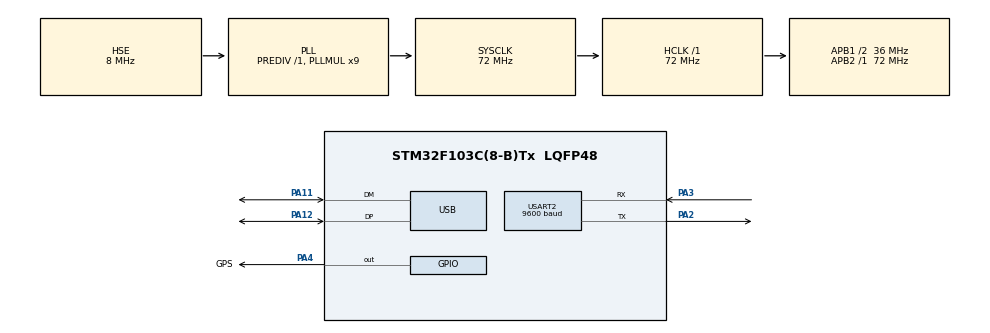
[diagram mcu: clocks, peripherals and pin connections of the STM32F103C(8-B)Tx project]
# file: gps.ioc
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Mcu.Family=STM32F1
Mcu.Name=STM32F103C(8-B)Tx
Mcu.Package=LQFP48
NVIC.PriorityGroup=NVIC_PRIORITYGROUP_4
NVIC.USART2_IRQn=true\:0\:0\:false\:false\:true\:true\:true\:true
NVIC.USB_LP_CAN1_RX0_IRQn=true\:0\:0\:false\:false\:true\:false\:true\:true
PA11.Mode=Device
PA11.Signal=USB_DM
PA12.Mode=Device
PA12.Signal=USB_DP
PA13.Mode=Serial_Wire
PA13.Signal=SYS_JTMS-SWDIO
PA14.Mode=Serial_Wire
PA14.Signal=SYS_JTCK-SWCLK
PA2.Mode=Asynchronous
PA2.Signal=USART2_TX
PA3.Mode=Asynchronous
PA3.Signal=USART2_RX
PA4.GPIO_Label=GPS
PA4.Signal=GPIO_Output
PD0-OSC_IN.Mode=HSE-External-Oscillator
PD0-OSC_IN.Signal=RCC_OSC_IN
PD1-OSC_OUT.Mode=HSE-External-Oscillator
PD1-OSC_OUT.Signal=RCC_OSC_OUT
ProjectManager.HeapSize=0x400
ProjectManager.StackSize=0x800
ProjectManager.TargetToolchain=STM32CubeIDE
RCC.AHBFreq_Value=72000000
RCC.APB1CLKDivider=RCC_HCLK_DIV2
RCC.APB1Freq_Value=36000000
RCC.APB1TimFreq_Value=72000000
RCC.APB2Freq_Value=72000000
RCC.APB2TimFreq_Value=72000000
RCC.HCLKFreq_Value=72000000
RCC.PLLMUL=RCC_PLL_MUL9
RCC.SYSCLKFreq_VALUE=72000000
RCC.SYSCLKSource=RCC_SYSCLKSOURCE_PLLCLK
RCC.USBFreq_Value=48000000
RCC.USBPrescaler=RCC_USBCLKSOURCE_PLL_DIV1_5
USART2.BaudRate=9600
USART2.VirtualMode=VM_ASYNC
USB_DEVICE.CLASS_NAME_FS=CDC
USB_DEVICE.VirtualMode=Cdc
USB_DEVICE.VirtualModeFS=Cdc_FS
VP_USB_DEVICE_VS_USB_DEVICE_CDC_FS.Mode=CDC_FS
board=custom

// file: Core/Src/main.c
/* USER CODE BEGIN Header */
/**
  ******************************************************************************
  * @file           : main.c
  * @brief          : Main program body
  ******************************************************************************
  * @attention
  *
  * <h2><center>&copy; Copyright (c) 2019 STMicroelectronics.
  * All rights reserved.</center></h2>
  *
  * This software component is licensed by ST under BSD 3-Clause license,
  * the "License"; You may not use this file except in compliance with the
  * License. You may obtain a copy of the License at:
  *                        opensource.org/licenses/BSD-3-Clause
  *
  ******************************************************************************
  */
/* USER CODE END Header */

#include "main.h"
#include "usart.h"
#include "usb_device.h"
#include "gpio.h"

/* USER CODE BEGIN Includes */
#include "gps.h"
/* USER CODE END Includes */

void SystemClock_Config(void);

/* USER CODE BEGIN 0 */

void HAL_UART_RxCpltCallback(UART_HandleTypeDef *huart)
{
	if(huart == &huart2) GPS_UART_CallBack();
}

/* USER CODE END 0 */

int main(void)
{

  /* MCU Configuration--------------------------------------------------------*/

  /* Reset of all peripherals, Initializes the Flash interface and the Systick. */
  HAL_Init();

  /* Configure the system clock */
  SystemClock_Config();

  /* Initialize all configured peripherals */
  MX_GPIO_Init();
  MX_USART2_UART_Init();
  MX_USB_DEVICE_Init();
  /* USER CODE BEGIN 2 */

  HAL_GPIO_WritePin(GPS_GPIO_Port, GPS_Pin, GPIO_PIN_SET);
  GPS_Init();

  /* USER CODE END 2 */

  /* Infinite loop */
  while (1)
  {

  }
}

void SystemClock_Config(void)
{
  RCC_OscInitTypeDef RCC_OscInitStruct = {0};
  RCC_ClkInitTypeDef RCC_ClkInitStruct = {0};
  RCC_PeriphCLKInitTypeDef PeriphClkInit = {0};

  /** Initializes the CPU, AHB and APB busses clocks
  */
  RCC_OscInitStruct.OscillatorType = RCC_OSCILLATORTYPE_HSE;
  RCC_OscInitStruct.HSEState = RCC_HSE_ON;
  RCC_OscInitStruct.HSEPredivValue = RCC_HSE_PREDIV_DIV1;
  RCC_OscInitStruct.HSIState = RCC_HSI_ON;
  RCC_OscInitStruct.PLL.PLLState = RCC_PLL_ON;
  RCC_OscInitStruct.PLL.PLLSource = RCC_PLLSOURCE_HSE;
  RCC_OscInitStruct.PLL.PLLMUL = RCC_PLL_MUL9;
  if (HAL_RCC_OscConfig(&RCC_OscInitStruct) != HAL_OK)
  {
    Error_Handler();
  }
  /** Initializes the CPU, AHB and APB busses clocks
  */
  RCC_ClkInitStruct.ClockType = RCC_CLOCKTYPE_HCLK|RCC_CLOCKTYPE_SYSCLK
                              |RCC_CLOCKTYPE_PCLK1|RCC_CLOCKTYPE_PCLK2;
  RCC_ClkInitStruct.SYSCLKSource = RCC_SYSCLKSOURCE_PLLCLK;
  RCC_ClkInitStruct.AHBCLKDivider = RCC_SYSCLK_DIV1;
  RCC_ClkInitStruct.APB1CLKDivider = RCC_HCLK_DIV2;
  RCC_ClkInitStruct.APB2CLKDivider = RCC_HCLK_DIV1;

  if (HAL_RCC_ClockConfig(&RCC_ClkInitStruct, FLASH_LATENCY_2) != HAL_OK)
  {
    Error_Handler();
  }
  PeriphClkInit.PeriphClockSelection = RCC_PERIPHCLK_USB;
  PeriphClkInit.UsbClockSelection = RCC_USBCLKSOURCE_PLL_DIV1_5;
  if (HAL_RCCEx_PeriphCLKConfig(&PeriphClkInit) != HAL_OK)
  {
    Error_Handler();
  }
}

void Error_Handler(void)
{
}

/************************ (C) COPYRIGHT STMicroelectronics *****END OF FILE****/
